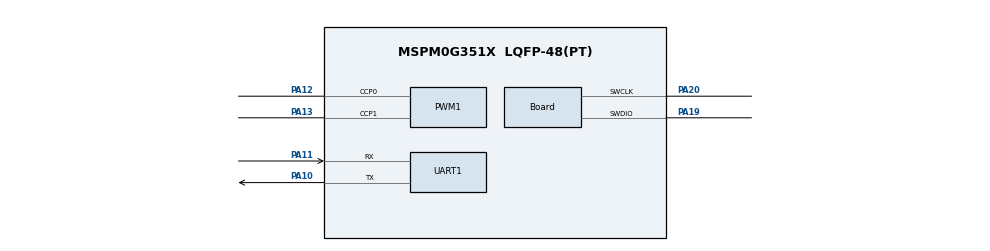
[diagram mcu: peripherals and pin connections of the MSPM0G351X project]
/**
 * @cliArgs --device "MSPM0G351X" --part "Default" --package "LQFP-48(PT)" --product "mspm0_sdk@2.02.00.05"
 * @versions {"tool":"1.21.1+3772"}
 */

/**
 * Import the modules used in this configuration.
 */
const PWM     = scripting.addModule("/ti/driverlib/PWM", {}, false);
const PWM1    = PWM.addInstance();
const SYSCTL  = scripting.addModule("/ti/driverlib/SYSCTL");
const SYSTICK = scripting.addModule("/ti/driverlib/SYSTICK");
const UART    = scripting.addModule("/ti/driverlib/UART", {}, false);
const UART1   = UART.addInstance();

/**
 * Write custom configuration values to the imported modules.
 */
const gate7  = system.clockTree["MFCLKGATE"];
gate7.enable = true;

PWM1.$name                      = "PWM_0";
PWM1.clockDivider               = 8;
PWM1.clockPrescale              = 200;
PWM1.timerCount                 = 400;
PWM1.peripheral.$assign         = "TIMG0";
PWM1.peripheral.ccp0Pin.$assign = "PA12";
PWM1.peripheral.ccp1Pin.$assign = "PA13";
PWM1.PWM_CHANNEL_0.$name        = "ti_driverlib_pwm_PWMTimerCC0";
PWM1.PWM_CHANNEL_0.dutyCycle    = 50;
PWM1.PWM_CHANNEL_0.invert       = true;
PWM1.PWM_CHANNEL_1.$name        = "ti_driverlib_pwm_PWMTimerCC1";
PWM1.PWM_CHANNEL_1.dutyCycle    = 50;
PWM1.PWM_CHANNEL_1.invert       = true;
PWM1.ccp0PinConfig.$name        = "ti_driverlib_gpio_GPIOPinGeneric4";
PWM1.ccp1PinConfig.$name        = "ti_driverlib_gpio_GPIOPinGeneric5";

const Board                       = scripting.addModule("/ti/driverlib/Board", {}, false);
Board.peripheral.$assign          = "DEBUGSS";
Board.peripheral.swclkPin.$assign = "PA20";
Board.peripheral.swdioPin.$assign = "PA19";

SYSCTL.forceDefaultClkConfig = true;
SYSCTL.clockTreeEn           = true;

SYSTICK.periodEnable      = true;
SYSTICK.period            = 32000;
SYSTICK.interruptEnable   = true;
SYSTICK.interruptPriority = "0";
SYSTICK.systickEnable     = true;

UART1.$name                    = "UART_0";
UART1.uartClkSrc               = "MFCLK";
UART1.enabledInterrupts        = ["RX"];
UART1.targetBaudRate           = 115200;
UART1.peripheral.$assign       = "UART0";
UART1.peripheral.rxPin.$assign = "PA11";
UART1.peripheral.txPin.$assign = "PA10";
UART1.txPinConfig.$name        = "ti_driverlib_gpio_GPIOPinGeneric0";
UART1.rxPinConfig.$name        = "ti_driverlib_gpio_GPIOPinGeneric1";

const ProjectConfig              = scripting.addModule("/ti/project_config/ProjectConfig", {}, false);
ProjectConfig.migrationCondition = true;
